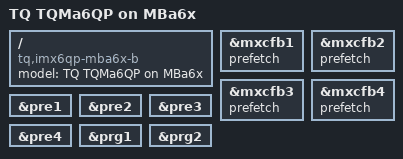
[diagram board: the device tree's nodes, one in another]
// SPDX-License-Identifier: GPL-2.0-only
/*
 * Copyright 2015-2021 TQ-Systems GmbH
 * Author: Markus Niebel <Markus.Niebel@tq-group.com>
 */
/dts-v1/;

#include <dt-bindings/gpio/gpio.h>
#include "imx6qp-tqma6b.dtsi"
#include "imx6qdl-mba6.dtsi"
#include "imx6qdl-mba6b.dtsi"
#include "imx6q-mba6.dtsi"

/ {
	model = "TQ TQMa6QP on MBa6x";
	compatible = "tq,imx6qp-mba6x-b", "tq,mba6b",
		     "tq,imx6qp-tqma6qp-b", "fsl,imx6qp";
};

&mxcfb1 {
	prefetch;
};

&mxcfb2 {
	prefetch;
};

&mxcfb3 {
	prefetch;
};

&mxcfb4 {
	prefetch;
};

&pre1 {
	status = "okay";
};

&pre2 {
	status = "okay";
};

&pre3 {
	status = "okay";
};

&pre4 {
	status = "okay";
};

&prg1 {
	status = "okay";
};

&prg2 {
	status = "okay";
};
